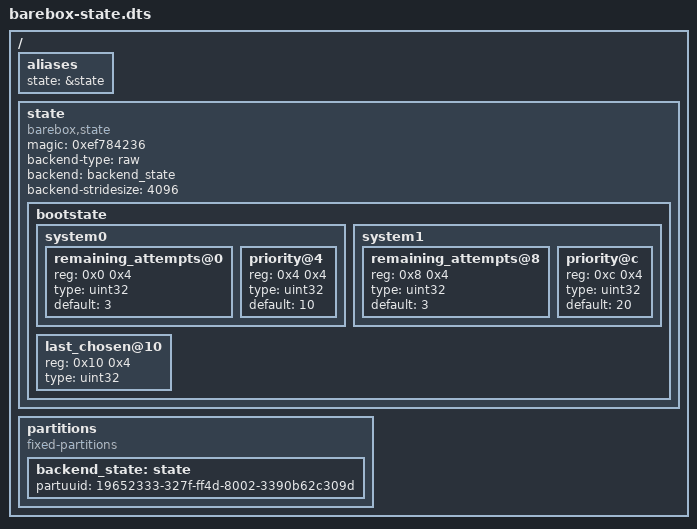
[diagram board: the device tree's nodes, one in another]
/dts-v1/;
/ {
	#address-cells = <1>;
	#size-cells = <1>;

	aliases {
		state = &state;
	};

	state: state {
                magic = <0xef784236>;
                compatible = "barebox,state";
                backend-type = "raw";
                backend = <&backend_state>;
                backend-stridesize = <4096>;

		bootstate {
			#address-cells = <1>;
			#size-cells = <1>;

			system0 {
				#address-cells = <1>;
				#size-cells = <1>;
				remaining_attempts@0 {
					reg = <0x0 0x4>;
					type = "uint32";
					default = <3>;
				};
				priority@4 {
					reg = <0x4 0x4>;
					type = "uint32";
					default = <10>;
				};
			};
			system1 {
				#address-cells = <1>;
				#size-cells = <1>;
				remaining_attempts@8 {
					reg = <0x8 0x4>;
					type = "uint32";
					default = <3>;
				};
				priority@c {
					reg = <0xc 0x4>;
					type = "uint32";
					default = <20>;
				};
			};
			last_chosen@10 {
				reg = <0x10 0x4>;
				type = "uint32";
			};
		};
	};

	partitions {
		#address-cells = <1>;
		#size-cells = <1>;
		compatible = "fixed-partitions";

		backend_state: state {
			partuuid = "19652333-327f-ff4d-8002-3390b62c309d";

		};
	};
};

